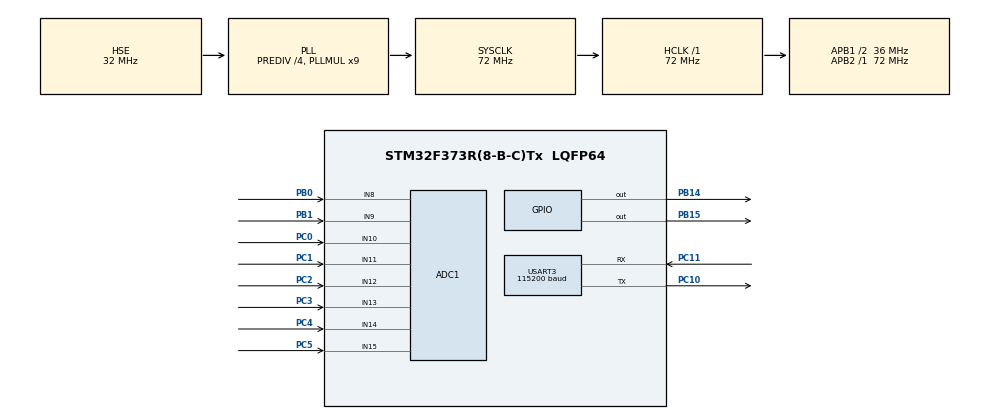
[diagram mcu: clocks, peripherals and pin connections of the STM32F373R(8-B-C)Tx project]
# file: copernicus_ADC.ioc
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ADC1.Channel-24\#ChannelRegularConversion=ADC_CHANNEL_8
ADC1.Channel-25\#ChannelRegularConversion=ADC_CHANNEL_9
ADC1.Channel-26\#ChannelRegularConversion=ADC_CHANNEL_10
ADC1.Channel-27\#ChannelRegularConversion=ADC_CHANNEL_11
ADC1.Channel-28\#ChannelRegularConversion=ADC_CHANNEL_12
ADC1.Channel-29\#ChannelRegularConversion=ADC_CHANNEL_13
ADC1.Channel-30\#ChannelRegularConversion=ADC_CHANNEL_14
ADC1.Channel-31\#ChannelRegularConversion=ADC_CHANNEL_15
ADC1.NbrOfConversion=8
ADC1.NbrOfConversionFlag=1
ADC1.Rank-24\#ChannelRegularConversion=1
ADC1.Rank-25\#ChannelRegularConversion=2
ADC1.Rank-26\#ChannelRegularConversion=3
ADC1.Rank-27\#ChannelRegularConversion=4
ADC1.Rank-28\#ChannelRegularConversion=5
ADC1.Rank-29\#ChannelRegularConversion=6
ADC1.Rank-30\#ChannelRegularConversion=7
ADC1.Rank-31\#ChannelRegularConversion=8
ADC1.SamplingTime-24\#ChannelRegularConversion=ADC_SAMPLETIME_1CYCLE_5
ADC1.SamplingTime-25\#ChannelRegularConversion=ADC_SAMPLETIME_1CYCLE_5
ADC1.SamplingTime-26\#ChannelRegularConversion=ADC_SAMPLETIME_1CYCLE_5
ADC1.SamplingTime-27\#ChannelRegularConversion=ADC_SAMPLETIME_1CYCLE_5
ADC1.SamplingTime-28\#ChannelRegularConversion=ADC_SAMPLETIME_1CYCLE_5
ADC1.SamplingTime-29\#ChannelRegularConversion=ADC_SAMPLETIME_1CYCLE_5
ADC1.SamplingTime-30\#ChannelRegularConversion=ADC_SAMPLETIME_1CYCLE_5
ADC1.SamplingTime-31\#ChannelRegularConversion=ADC_SAMPLETIME_1CYCLE_5
ADC1.master=1
Dma.ADC1.0.Direction=DMA_PERIPH_TO_MEMORY
Dma.ADC1.0.Instance=DMA1_Channel1
Dma.ADC1.0.MemDataAlignment=DMA_MDATAALIGN_HALFWORD
Dma.ADC1.0.MemInc=DMA_MINC_ENABLE
Dma.ADC1.0.Mode=DMA_NORMAL
Dma.ADC1.0.PeriphDataAlignment=DMA_PDATAALIGN_HALFWORD
Dma.ADC1.0.PeriphInc=DMA_PINC_DISABLE
Dma.ADC1.0.Priority=DMA_PRIORITY_LOW
Dma.Request0=ADC1
Mcu.Family=STM32F3
Mcu.Name=STM32F373R(8-B-C)Tx
Mcu.Package=LQFP64
NVIC.ADC1_IRQn=true\:0\:0\:false\:false\:true\:true\:true
NVIC.DMA1_Channel1_IRQn=true\:0\:0\:false\:false\:true\:false\:true
NVIC.PriorityGroup=NVIC_PRIORITYGROUP_4
PA13.Mode=Serial_Wire
PA13.Signal=SYS_JTMS-SWDIO
PA14.Mode=Serial_Wire
PA14.Signal=SYS_JTCK-SWCLK
PB0.Mode=IN8
PB0.Signal=ADC1_IN8
PB1.Mode=IN9
PB1.Signal=ADC1_IN9
PB14.Signal=GPIO_Output
PB15.Signal=GPIO_Output
PC0.Mode=IN10
PC0.Signal=ADC1_IN10
PC1.Mode=IN11
PC1.Signal=ADC1_IN11
PC10.Mode=Asynchronous
PC10.Signal=USART3_TX
PC11.Mode=Asynchronous
PC11.Signal=USART3_RX
PC14-OSC32_IN.Mode=LSE-External-Oscillator
PC14-OSC32_IN.Signal=RCC_OSC32_IN
PC15-OSC32_OUT.Mode=LSE-External-Oscillator
PC15-OSC32_OUT.Signal=RCC_OSC32_OUT
PC2.Mode=IN12
PC2.Signal=ADC1_IN12
PC3.Mode=IN13
PC3.Signal=ADC1_IN13
PC4.Mode=IN14
PC4.Signal=ADC1_IN14
PC5.Mode=IN15
PC5.Signal=ADC1_IN15
PF0-OSC_IN.Mode=HSE-External-Oscillator
PF0-OSC_IN.Signal=RCC_OSC_IN
PF1-OSC_OUT.Mode=HSE-External-Oscillator
PF1-OSC_OUT.Signal=RCC_OSC_OUT
ProjectManager.HeapSize=0x200
ProjectManager.StackSize=0x400
ProjectManager.TargetToolchain=SW4STM32
RCC.AHBFreq_Value=72000000
RCC.APB1CLKDivider=RCC_HCLK_DIV2
RCC.APB1Freq_Value=36000000
RCC.APB1TimFreq_Value=72000000
RCC.APB2Freq_Value=72000000
RCC.APB2TimFreq_Value=72000000
RCC.CortexFreq_Value=72000000
RCC.HCLKFreq_Value=72000000
RCC.HSE_VALUE=32000000
RCC.HSI_VALUE=8000000
RCC.PLLMUL=RCC_PLL_MUL9
RCC.PLLSourceVirtual=RCC_PLLSOURCE_HSE
RCC.RCC_PLLsource_Clock_Source_FROM_HSE=RCC_HSE_PREDIV_DIV4
RCC.SYSCLKFreq_VALUE=72000000
RCC.SYSCLKSource=RCC_SYSCLKSOURCE_PLLCLK
RCC.USBFreq_Value=72000000
USART3.BaudRate=115200
USART3.VirtualMode-Asynchronous=VM_ASYNC
board=custom

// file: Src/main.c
/* USER CODE BEGIN Header */
/**
  ******************************************************************************
  * @file           : main.c
  * @brief          : Main program body
  ******************************************************************************
  * @attention
  *
  * <h2><center>&copy; Copyright (c) 2019 STMicroelectronics.
  * All rights reserved.</center></h2>
  *
  * This software component is licensed by ST under BSD 3-Clause license,
  * the "License"; You may not use this file except in compliance with the
  * License. You may obtain a copy of the License at:
  *                        opensource.org/licenses/BSD-3-Clause
  *
  ******************************************************************************
  */
/* USER CODE END Header */

#include "main.h"
#include "adc.h"
#include "dma.h"
#include "usart.h"
#include "gpio.h"

void SystemClock_Config(void);

int main(void)
{

  /* MCU Configuration--------------------------------------------------------*/

  /* Reset of all peripherals, Initializes the Flash interface and the Systick. */
  HAL_Init();

  /* Configure the system clock */
  SystemClock_Config();

  /* Initialize all configured peripherals */
  MX_GPIO_Init();
  MX_ADC1_Init();
  MX_USART3_UART_Init();
  MX_DMA_Init();

  /* Infinite loop */
  /* USER CODE BEGIN WHILE */
  char buff[100];
  while (1)
  {
	  extWatchDogToggle();
	 // HAL_ADC_Start(&hadc1);
//	  HAL_ADC_PollForConversion(&hadc1,10);
//	  	  ADC_VAL[0]=HAL_ADC_GetValue(&hadc1);
//	  	 sprintf(buff,"adc  = %d \n",ADC_VAL[0]);
//	  			  stringOut(USART3,buff);
//	  			HAL_ADC_PollForConversion(&hadc1,10);
//	  				  	  ADC_VAL[0]=HAL_ADC_GetValue(&hadc1);
//	  				  	 sprintf(buff,"adc  = %d \n",ADC_VAL[0]);
//	  				  			  stringOut(USART3,buff);
//	  				  			HAL_ADC_PollForConversion(&hadc1,10);
//	  				  				  	  ADC_VAL[0]=HAL_ADC_GetValue(&hadc1);
//	  				  				  	 sprintf(buff,"adc  = %d \n",ADC_VAL[0]);
//	  				  				  			  stringOut(USART3,buff);
//	  				  				  		HAL_ADC_Stop(&hadc1);
	  HAL_ADC_Start_DMA(&hadc1,ADC_VAL, 7);
//	  HAL_ADC_Start_DMA(&hadc1,ADC_VAL, 3);
//	  HAL_ADC_Start_DMA(&hadc1,ADC_VAL, 3);
//	  HAL_ADC_Stop(&hadc1);
	 // HAL_ADC_Start(&hadc1);

//	  ADC1-> CR2 |= ADC_CR2_SWSTART;
    /* USER CODE END WHILE */

  }
}

void SystemClock_Config(void)
{
  RCC_OscInitTypeDef RCC_OscInitStruct = {0};
  RCC_ClkInitTypeDef RCC_ClkInitStruct = {0};
  RCC_PeriphCLKInitTypeDef PeriphClkInit = {0};

  /** Initializes the CPU, AHB and APB busses clocks
  */
  RCC_OscInitStruct.OscillatorType = RCC_OSCILLATORTYPE_HSE;
  RCC_OscInitStruct.HSEState = RCC_HSE_ON;
  RCC_OscInitStruct.HSEPredivValue = RCC_HSE_PREDIV_DIV4;
  RCC_OscInitStruct.HSIState = RCC_HSI_ON;
  RCC_OscInitStruct.PLL.PLLState = RCC_PLL_ON;
  RCC_OscInitStruct.PLL.PLLSource = RCC_PLLSOURCE_HSE;
  RCC_OscInitStruct.PLL.PLLMUL = RCC_PLL_MUL9;
  if (HAL_RCC_OscConfig(&RCC_OscInitStruct) != HAL_OK)
  {
    Error_Handler();
  }
  /** Initializes the CPU, AHB and APB busses clocks
  */
  RCC_ClkInitStruct.ClockType = RCC_CLOCKTYPE_HCLK|RCC_CLOCKTYPE_SYSCLK
                              |RCC_CLOCKTYPE_PCLK1|RCC_CLOCKTYPE_PCLK2;
  RCC_ClkInitStruct.SYSCLKSource = RCC_SYSCLKSOURCE_PLLCLK;
  RCC_ClkInitStruct.AHBCLKDivider = RCC_SYSCLK_DIV1;
  RCC_ClkInitStruct.APB1CLKDivider = RCC_HCLK_DIV2;
  RCC_ClkInitStruct.APB2CLKDivider = RCC_HCLK_DIV1;

  if (HAL_RCC_ClockConfig(&RCC_ClkInitStruct, FLASH_LATENCY_2) != HAL_OK)
  {
    Error_Handler();
  }
  PeriphClkInit.PeriphClockSelection = RCC_PERIPHCLK_USART3|RCC_PERIPHCLK_ADC1;
  PeriphClkInit.Usart3ClockSelection = RCC_USART3CLKSOURCE_PCLK1;
  PeriphClkInit.Adc1ClockSelection = RCC_ADC1PCLK2_DIV2;

  if (HAL_RCCEx_PeriphCLKConfig(&PeriphClkInit) != HAL_OK)
  {
    Error_Handler();
  }
}

void Error_Handler(void)
{
}

/************************ (C) COPYRIGHT STMicroelectronics *****END OF FILE****/
